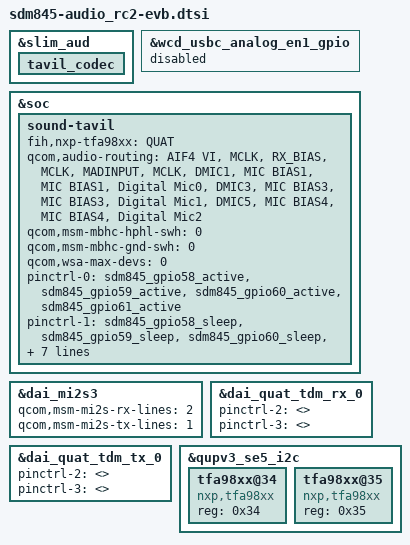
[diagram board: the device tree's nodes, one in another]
/*
 * Copyright (c) 2017, The Linux Foundation. All rights reserved.
 *
 * This program is free software; you can redistribute it and/or modify
 * it under the terms of the GNU General Public License version 2 and
 * only version 2 as published by the Free Software Foundation.
 *
 * This program is distributed in the hope that it will be useful,
 * but WITHOUT ANY WARRANTY; without even the implied warranty of
 * MERCHANTABILITY or FITNESS FOR A PARTICULAR PURPOSE.  See the
 * GNU General Public License for more details.
 */

&slim_aud {
	tavil_codec {
		/delete-node/ swr_master;
		/delete-node/ wcd;
	};
};

&wcd_usbc_analog_en1_gpio {
	status = "disabled";
};

&soc {
	sound-tavil {
		fih,nxp-tfa98xx = "QUAT"; //Choose QUAT MI2S Interface
		qcom,audio-routing =
		"AIF4 VI", "MCLK",
		"RX_BIAS", "MCLK",
		"MADINPUT", "MCLK",
		"DMIC1", "MIC BIAS1",
		"MIC BIAS1", "Digital Mic0",
		"DMIC3", "MIC BIAS3",
		"MIC BIAS3", "Digital Mic1",
		"DMIC5", "MIC BIAS4",
		"MIC BIAS4", "Digital Mic2";

		qcom,msm-mbhc-hphl-swh = <0>;
		qcom,msm-mbhc-gnd-swh = <0>;
		qcom,wsa-max-devs = <0>;
		/delete-property/ qcom,hph-en0-gpio;
		/delete-property/ qcom,hph-en1-gpio;
		/delete-property/ qcom,wsa-devs;
		/delete-property/ qcom,wsa-aux-dev-prefix;

		pinctrl-names = "quat-mi2s-active", "quat-mi2s-sleep",
				"quat-tdm-active", "quat-tdm-sleep";
		pinctrl-0 = <&sdm845_gpio58_active &sdm845_gpio59_active
				&sdm845_gpio60_active &sdm845_gpio61_active>;
		pinctrl-1 = <&sdm845_gpio58_sleep &sdm845_gpio59_sleep
				&sdm845_gpio60_sleep &sdm845_gpio61_sleep>;
		pinctrl-2 = <&sdm845_gpio58_active &sdm845_gpio59_active
				&sdm845_gpio60_active &sdm845_gpio61_active>;
		pinctrl-3 = <&sdm845_gpio58_sleep &sdm845_gpio59_sleep
				&sdm845_gpio60_sleep &sdm845_gpio61_sleep>;     
	};
};

&dai_mi2s3 {
	qcom,msm-mi2s-rx-lines = <2>;
	qcom,msm-mi2s-tx-lines = <1>;
};

&dai_quat_tdm_rx_0 {
	pinctrl-2 = <>;
	pinctrl-3 = <>;
};

&dai_quat_tdm_tx_0 {
	pinctrl-2 = <>;
	pinctrl-3 = <>;
};

&qupv3_se5_i2c {
	status = "ok";
	tfa98xx@34 {
		compatible = "nxp,tfa98xx";
		reg = <0x34>;
	};
	tfa98xx@35 {
		compatible = "nxp,tfa98xx";
		reg = <0x35>;
	};
};
